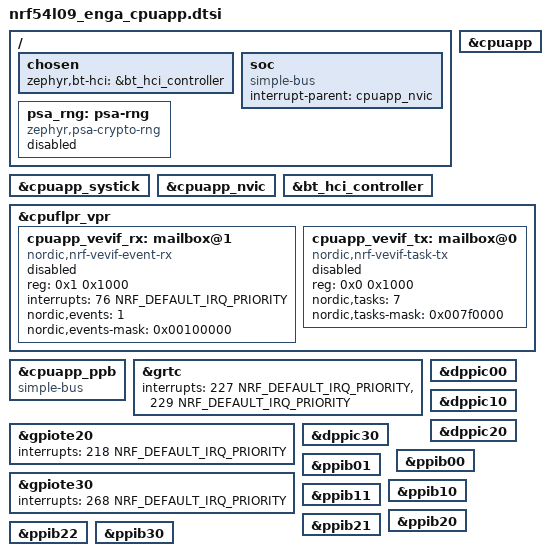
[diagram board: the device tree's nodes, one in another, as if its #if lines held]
/*
 * Copyright (c) 2024 Nordic Semiconductor ASA
 *
 * SPDX-License-Identifier: Apache-2.0
 */

#include <nordic/nrf54l09.dtsi>

cpu: &cpuapp {};
systick: &cpuapp_systick {};
nvic: &cpuapp_nvic {};

/delete-node/ &cpuflpr;
/delete-node/ &cpuflpr_rram;
/delete-node/ &cpuflpr_sram;
/delete-node/ &cpuflpr_clic;

/ {
	chosen {
		zephyr,bt-hci = &bt_hci_controller;
	};

	soc {
		compatible = "simple-bus";
		interrupt-parent = <&cpuapp_nvic>;
		ranges;
	};

	psa_rng: psa-rng {
		compatible = "zephyr,psa-crypto-rng";
		status = "disabled";
	};
};

&bt_hci_controller {
	status = "okay";
};

&cpuflpr_vpr {
	cpuapp_vevif_rx: mailbox@1 {
		compatible = "nordic,nrf-vevif-event-rx";
		reg = <0x1 0x1000>;
		status = "disabled";
		interrupts = <76 NRF_DEFAULT_IRQ_PRIORITY>;
		#mbox-cells = <1>;
		nordic,events = <1>;
		nordic,events-mask = <0x00100000>;
	};

	cpuapp_vevif_tx: mailbox@0 {
		compatible = "nordic,nrf-vevif-task-tx";
		reg = <0x0 0x1000>;
		#mbox-cells = <1>;
		nordic,tasks = <7>;
		nordic,tasks-mask = <0x007f0000>;
		status = "disabled";
	};
};

&cpuapp_ppb {
	compatible = "simple-bus";
	ranges;
};

&grtc {
#ifdef USE_NON_SECURE_ADDRESS_MAP
	interrupts = <227 NRF_DEFAULT_IRQ_PRIORITY>,
#else
	interrupts = <228 NRF_DEFAULT_IRQ_PRIORITY>,
#endif
		<229 NRF_DEFAULT_IRQ_PRIORITY>; /* reserved for Zero Latency IRQs */
};

&gpiote20 {
#ifdef USE_NON_SECURE_ADDRESS_MAP
	interrupts = <218 NRF_DEFAULT_IRQ_PRIORITY>;
#else
	interrupts = <219 NRF_DEFAULT_IRQ_PRIORITY>;
#endif
};

&gpiote30 {
#ifdef USE_NON_SECURE_ADDRESS_MAP
	interrupts = <268 NRF_DEFAULT_IRQ_PRIORITY>;
#else
	interrupts = <269 NRF_DEFAULT_IRQ_PRIORITY>;
#endif
};

&dppic00 {
	status = "okay";
};

&dppic10 {
	status = "okay";
};

&dppic20 {
	status = "okay";
};

&dppic30 {
	status = "okay";
};

&ppib00 {
	status = "okay";
};

&ppib01 {
	status = "okay";
};

&ppib10 {
	status = "okay";
};

&ppib11 {
	status = "okay";
};

&ppib20 {
	status = "okay";
};

&ppib21 {
	status = "okay";
};

&ppib22 {
	status = "okay";
};

&ppib30 {
	status = "okay";
};
